# I2CM register map
Vendor: Texas Instruments
Peripheral module from a debugger description file (folder cc2538).
Registers are 32-bit, access per field, no defined reset value unless marked. A register's access mark holds for its fields unless they carry their own. Offsets are as the file gives them; lines under a group give offsets from that group; [hi:lo] are bit positions; {n}, {i} and the like mark numbered series; 'fields as' and 'values as' point back to an identical list; <NAME> marks a mode.

## I2CM — Register fields should be considered static unless otherwise noted as dynamic.
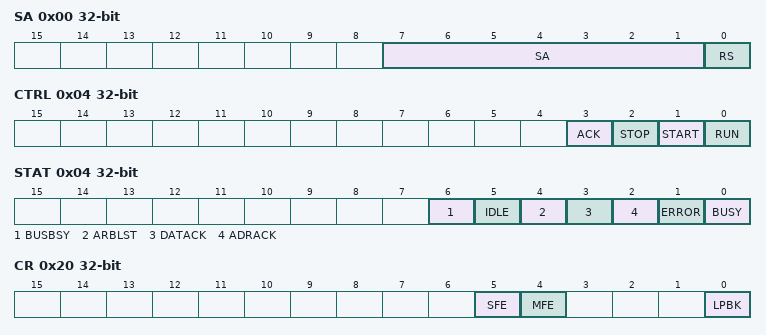
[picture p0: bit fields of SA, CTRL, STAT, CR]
0x00 SA — I2C master slave address This register consists of eight bits, seven address bits (A6-A0), and a receive and send bit, which determines if the next operation is a receive (high) or transmit (low).
  [7:1] SA rw — I2C slave address
  [0] RS rw — Receive and send The R/S bit specifies if the next operation is a receive (high) or transmit (low). 0: Transmit 1: Receive
0x04 CTRL wo — I2C master control and status This register accesses status bits when read and control bits when written. When read, the status register indicates the state of the I2C bus controller. When written, the control register configures the I2C controller operation. The START bit generates the START or REPEATED START condition. The STOP bit determines if the cycle stops at the end of the data cycle or continues on to a repeated START condition. To generate a single transmit cycle, the I2C master slave address (I2CMSA) register is written with the desired address, the R/S bit is cleared, and this register is written with ACK = X (0 or 1), STOP = 1, START = 1, and RUN = 1 to perform the operation and stop. When the operation is completed (or aborted due an error), an interrupt becomes active and the data may be read from the I2CMDR register. When the I2C module operates in master receiver mode, the ACK bit is normally set, causing the I2C bus controller to automatically transmit an acknowledge after each byte. This bit must be cleared when the I2C bus controller requires no further data to be transmitted from the slave transmitter.
  [3] ACK — Data acknowledge enable 0: The received data byte is not acknowledged automatically by the master. 1: The received data byte is acknowledged automatically by the master.
  [2] STOP — Generate STOP 0: The controller does not generate the STOP condition. 1: The controller generates the STOP condition.
  [1] START — Generate START 0: The controller does not generate the START condition. 1: The controller generates the START condition.
  [0] RUN — I2C master enable 0: The master is disabled. 1: The master is enabled to transmit or receive data. When the BUSY bit is set, the other status bits are not valid.
0x04 STAT ro — I2C master control and status This register accesses status bits when read and control bits when written. When read, the status register indicates the state of the I2C bus controller. When written, the control register configures the I2C controller operation. The START bit generates the START or REPEATED START condition. The STOP bit determines if the cycle stops at the end of the data cycle or continues on to a repeated START condition. To generate a single transmit cycle, the I2C master slave address (I2CMSA) register is written with the desired address, the R/S bit is cleared, and this register is written with ACK = X (0 or 1), STOP = 1, START = 1, and RUN = 1 to perform the operation and stop. When the operation is completed (or aborted due an error), an interrupt becomes active and the data may be read from the I2CMDR register. When the I2C module operates in master receiver mode, the ACK bit is normally set, causing the I2C bus controller to automatically transmit an acknowledge after each byte. This bit must be cleared when the I2C bus controller requires no further data to be transmitted from the slave transmitter.
  [6] BUSBSY — Bus busy 0: The I2C bus is idle. 1: The I2C bus is busy. The bit changes based on the START and STOP conditions.
  [5] IDLE — I2C idle 0: The I2C controller is not idle. 1: The I2C controller is idle.
  [4] ARBLST — Arbitration lost 0: The I2C controller won arbitration. 1: The I2C controller lost arbitration.
  [3] DATACK — Acknowledge data 0: The transmited data was acknowledged. 1: The transmited data was not acknowledged.
  [2] ADRACK — Acknowledge address 0: The transmited address was acknowledged. 1: The transmited address was not acknowledged.
  [1] ERROR — Error 0: No error was detected on the last operation. 1: An error occurred on the last operation.
  [0] BUSY — I2C busy 0: The controller is idle. 1: The controller is busy. When the BUSY bit is set, the other status bits are not valid.
0x08 DR — I2C master data This register contains the data to be transmitted when in the master transmit state and the data received when in the master receive state.
  [7:0] DATA rw — Data transferred Data transferred during transaction
0x0C TPR — I2C master timer period This register specifies the period of the SCL clock.
  [6:0] TPR rw — SCL clock period This field specifies the period of the SCL clock. SCL_PRD = 2 * (1+TPR)*(SCL_LP + SCL_HP)*CLK_PRD where: SCL_PRD is the SCL line period (I2C clock). TPR is the timer period register value (range of 1 to 127) SCL_LP is the SCL low period (fixed at 6). SCL_HP is the SCL high period (fixed at 4). CLK_PRD is the system clock period in ns.
0x10 IMR — I2C master interrupt mask This register controls whether a raw interrupt is promoted to a controller interrupt.
  [0] IM rw — Interrupt mask 1: The master interrupt is sent to the interrupt controller when the RIS bit in the I2CMRIS register is set. 0: The RIS interrupt is suppressed and not sent to the interrupt controller.
0x14 RIS ro — I2C master raw interrupt status This register specifies whether an interrupt is pending.
  [0] RIS — Raw interrupt status 1: A master interrupt is pending. 0: No interrupt This bit is cleared by writing 1 to the IC bit in the I2CMICR register.
0x18 MIS ro — I2C master masked interrupt status This register specifies whether an interrupt was signaled.
  [0] MIS — Masked interrupt status 1: An unmasked master interrupt is pending. 0: An interrupt has not occurred or is masked. This bit is cleared by writing 1 to the IC bit in the I2CMICR register.
0x1C ICR wo — I2C master interrupt clear This register clears the raw and masked interrupts.
  [0] IC — Interrupt clear Writing 1 to this bit clears the RIS bit in the I2CMRIS register and the MIS bit in the I2CMMIS register. Reading this register returns no meaningful data.
0x20 CR — I2C master configuration This register configures the mode (master or slave) and sets the interface for test mode loopback.
  [5] SFE rw — I2C slave function enable 1: Slave mode is enabled. 0: Slave mode is disabled.
  [4] MFE rw — I2C master function enable 1: Master mode is enabled. 0: Master mode is disabled.
  [0] LPBK rw — I2C loopback 1: The controller in a test mode loopback configuration. 0: Normal operation
